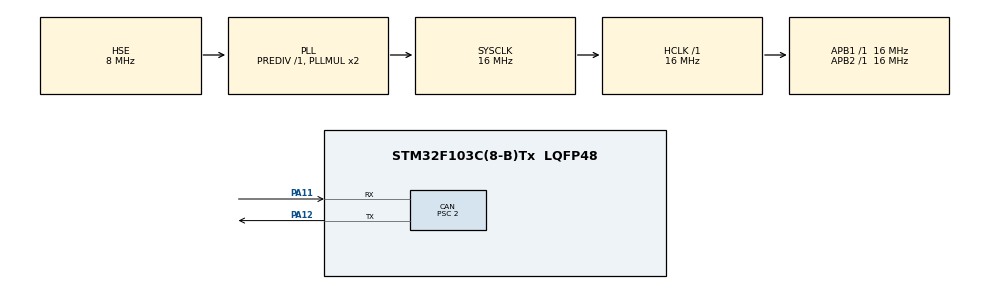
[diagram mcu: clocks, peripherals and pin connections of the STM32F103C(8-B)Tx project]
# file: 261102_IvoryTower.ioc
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CAN.ABOM=ENABLE
CAN.BS1=CAN_BS1_13TQ
CAN.BS2=CAN_BS2_2TQ
CAN.CalculateBaudRate=500000
CAN.CalculateTimeBit=2000
CAN.CalculateTimeQuantum=125.0
CAN.NART=ENABLE
CAN.Prescaler=2
Mcu.Family=STM32F1
Mcu.Name=STM32F103C(8-B)Tx
Mcu.Package=LQFP48
NVIC.PriorityGroup=NVIC_PRIORITYGROUP_4
NVIC.USB_LP_CAN1_RX0_IRQn=true\:6\:0\:true\:false\:true\:true\:true
PA11.Mode=CAN_Activate
PA11.Signal=CAN_RX
PA12.Mode=CAN_Activate
PA12.Signal=CAN_TX
PA13.Mode=Serial_Wire
PA13.Signal=SYS_JTMS-SWDIO
PA14.Mode=Serial_Wire
PA14.Signal=SYS_JTCK-SWCLK
PC14-OSC32_IN.Mode=LSE-External-Oscillator
PC14-OSC32_IN.Signal=RCC_OSC32_IN
PC15-OSC32_OUT.Mode=LSE-External-Oscillator
PC15-OSC32_OUT.Signal=RCC_OSC32_OUT
PD0-OSC_IN.Mode=HSE-External-Oscillator
PD0-OSC_IN.Signal=RCC_OSC_IN
PD1-OSC_OUT.Mode=HSE-External-Oscillator
PD1-OSC_OUT.Signal=RCC_OSC_OUT
ProjectManager.HeapSize=0x200
ProjectManager.StackSize=0x400
ProjectManager.TargetToolchain=MDK-ARM V5.32
RCC.AHBFreq_Value=16000000
RCC.APB1Freq_Value=16000000
RCC.APB1TimFreq_Value=16000000
RCC.APB2Freq_Value=16000000
RCC.APB2TimFreq_Value=16000000
RCC.HCLKFreq_Value=16000000
RCC.PLLSourceVirtual=RCC_PLLSOURCE_HSE
RCC.SYSCLKFreq_VALUE=16000000
RCC.SYSCLKSource=RCC_SYSCLKSOURCE_PLLCLK
RCC.USBFreq_Value=16000000
board=custom

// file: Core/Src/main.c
/* USER CODE BEGIN Header */
/**
  ******************************************************************************
  * @file           : main.c
  * @brief          : Main program body
  ******************************************************************************
  * @attention
  *
  * Copyright (c) 2026 STMicroelectronics.
  * All rights reserved.
  *
  * This software is licensed under terms that can be found in the LICENSE file
  * in the root directory of this software component.
  * If no LICENSE file comes with this software, it is provided AS-IS.
  *
  ******************************************************************************
  */
/* USER CODE END Header */
#include "main.h"
#include "can.h"
#include "gpio.h"

void SystemClock_Config(void);

/* USER CODE BEGIN 0 */
typedef struct{
		uint16_t angle;
		int16_t rpm;
		int16_t current;
		uint8_t tempreature;

		}Motor;
		Motor motor_1;
/* USER CODE END 0 */

int main(void)
{

  /* MCU Configuration--------------------------------------------------------*/

  /* Reset of all peripherals, Initializes the Flash interface and the Systick. */
  HAL_Init();

  /* Configure the system clock */
  SystemClock_Config();

  /* Initialize all configured peripherals */
  MX_GPIO_Init();
  MX_CAN_Init();
  /* USER CODE BEGIN 2 */

CAN_FilterTypeDef f;
f.FilterBank           = 0;
f.FilterMode           = CAN_FILTERMODE_IDMASK;
f.FilterScale          = CAN_FILTERSCALE_32BIT;
f.FilterIdHigh         = (0x200 & 0x7FF) << 5;
f.FilterIdLow          = 0;
f.FilterMaskIdHigh     = (0x7F8 & 0x7FF) << 5;
f.FilterMaskIdLow      = 0;
f.FilterFIFOAssignment = CAN_RX_FIFO0;
f.FilterActivation     = ENABLE;
HAL_CAN_ConfigFilter(&hcan, &f);

HAL_CAN_Start(&hcan);
HAL_CAN_ActivateNotification(&hcan, CAN_IT_RX_FIFO0_MSG_PENDING);

  /* USER CODE END 2 */

  /* Infinite loop */
  while (1)
  {

  }
}

void SystemClock_Config(void)
{
  RCC_OscInitTypeDef RCC_OscInitStruct = {0};
  RCC_ClkInitTypeDef RCC_ClkInitStruct = {0};

  /** Initializes the RCC Oscillators according to the specified parameters
  * in the RCC_OscInitTypeDef structure.
  */
  RCC_OscInitStruct.OscillatorType = RCC_OSCILLATORTYPE_HSE;
  RCC_OscInitStruct.HSEState = RCC_HSE_ON;
  RCC_OscInitStruct.HSEPredivValue = RCC_HSE_PREDIV_DIV1;
  RCC_OscInitStruct.HSIState = RCC_HSI_ON;
  RCC_OscInitStruct.PLL.PLLState = RCC_PLL_ON;
  RCC_OscInitStruct.PLL.PLLSource = RCC_PLLSOURCE_HSE;
  RCC_OscInitStruct.PLL.PLLMUL = RCC_PLL_MUL2;
  if (HAL_RCC_OscConfig(&RCC_OscInitStruct) != HAL_OK)
  {
    Error_Handler();
  }
  /** Initializes the CPU, AHB and APB buses clocks
  */
  RCC_ClkInitStruct.ClockType = RCC_CLOCKTYPE_HCLK|RCC_CLOCKTYPE_SYSCLK
                              |RCC_CLOCKTYPE_PCLK1|RCC_CLOCKTYPE_PCLK2;
  RCC_ClkInitStruct.SYSCLKSource = RCC_SYSCLKSOURCE_PLLCLK;
  RCC_ClkInitStruct.AHBCLKDivider = RCC_SYSCLK_DIV1;
  RCC_ClkInitStruct.APB1CLKDivider = RCC_HCLK_DIV1;
  RCC_ClkInitStruct.APB2CLKDivider = RCC_HCLK_DIV1;

  if (HAL_RCC_ClockConfig(&RCC_ClkInitStruct, FLASH_LATENCY_0) != HAL_OK)
  {
    Error_Handler();
  }
}

/* USER CODE BEGIN 4 */
void HAL_CAN_RxFifo0MsgPendingCallback(CAN_HandleTypeDef *hcan){
		CAN_RxHeaderTypeDef rx;
    uint8_t d[8];
    HAL_CAN_GetRxMessage(hcan, CAN_RX_FIFO0, &rx, d);

		motor_1.angle = (uint16_t)(d[0] << 8) | d[1];
		motor_1.rpm = (int16_t)(d[2] << 8) | d[3];
		motor_1.current = (int16_t)(d[4] << 8) | d[5];
		motor_1.tempreature = (uint8_t)d[6];

}
/* USER CODE END 4 */

void Error_Handler(void)
{
  __disable_irq();
  while (1)
  {
  }
}
